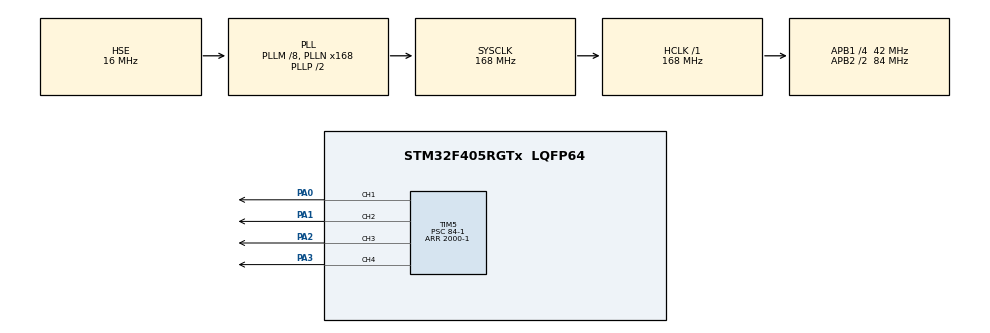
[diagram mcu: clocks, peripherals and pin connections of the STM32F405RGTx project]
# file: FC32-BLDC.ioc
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Mcu.Family=STM32F4
Mcu.Name=STM32F405RGTx
Mcu.Package=LQFP64
NVIC.PriorityGroup=NVIC_PRIORITYGROUP_4
PA0-WKUP.Signal=S_TIM5_CH1
PA1.Signal=S_TIM5_CH2
PA13.Mode=Serial_Wire
PA13.Signal=SYS_JTMS-SWDIO
PA14.Mode=Serial_Wire
PA14.Signal=SYS_JTCK-SWCLK
PA2.Signal=S_TIM5_CH3
PA3.Signal=S_TIM5_CH4
PH0-OSC_IN.Mode=HSE-External-Oscillator
PH0-OSC_IN.Signal=RCC_OSC_IN
PH1-OSC_OUT.Mode=HSE-External-Oscillator
PH1-OSC_OUT.Signal=RCC_OSC_OUT
ProjectManager.HeapSize=0x200
ProjectManager.StackSize=0x400
ProjectManager.TargetToolchain=STM32CubeIDE
RCC.48MHZClocksFreq_Value=84000000
RCC.AHBFreq_Value=168000000
RCC.APB1CLKDivider=RCC_HCLK_DIV4
RCC.APB1Freq_Value=42000000
RCC.APB1TimFreq_Value=84000000
RCC.APB2CLKDivider=RCC_HCLK_DIV2
RCC.APB2Freq_Value=84000000
RCC.APB2TimFreq_Value=168000000
RCC.CortexFreq_Value=168000000
RCC.HCLKFreq_Value=168000000
RCC.HSE_VALUE=16000000
RCC.HSI_VALUE=16000000
RCC.LSE_VALUE=32768
RCC.PLLM=8
RCC.PLLN=168
RCC.PLLSourceVirtual=RCC_PLLSOURCE_HSE
RCC.SYSCLKFreq_VALUE=168000000
RCC.SYSCLKSource=RCC_SYSCLKSOURCE_PLLCLK
RCC.VCOOutputFreq_Value=336000000
SH.S_TIM5_CH1.0=TIM5_CH1,PWM Generation1 CH1
SH.S_TIM5_CH2.0=TIM5_CH2,PWM Generation2 CH2
SH.S_TIM5_CH3.0=TIM5_CH3,PWM Generation3 CH3
SH.S_TIM5_CH4.0=TIM5_CH4,PWM Generation4 CH4
TIM5.Channel-PWM\ Generation1\ CH1=TIM_CHANNEL_1
TIM5.Channel-PWM\ Generation2\ CH2=TIM_CHANNEL_2
TIM5.Channel-PWM\ Generation3\ CH3=TIM_CHANNEL_3
TIM5.Channel-PWM\ Generation4\ CH4=TIM_CHANNEL_4
TIM5.Period=2000-1
TIM5.Prescaler=84-1
VP_TIM5_VS_ClockSourceINT.Mode=Internal
board=custom

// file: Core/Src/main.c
/* USER CODE BEGIN Header */
/**
  ******************************************************************************
  * @file           : main.c
  * @brief          : Main program body
  ******************************************************************************
  * @attention
  *
  * Copyright (c) 2022 STMicroelectronics.
  * All rights reserved.
  *
  * This software is licensed under terms that can be found in the LICENSE file
  * in the root directory of this software component.
  * If no LICENSE file comes with this software, it is provided AS-IS.
  *
  ******************************************************************************
  */
/* USER CODE END Header */
#include "main.h"
#include "tim.h"
#include "gpio.h"

/* USER CODE BEGIN PV */
uint16_t speed = 1100;
/* USER CODE END PV */

void SystemClock_Config(void);

int main(void)
{

  /* MCU Configuration--------------------------------------------------------*/

  /* Reset of all peripherals, Initializes the Flash interface and the Systick. */
  HAL_Init();

  /* Configure the system clock */
  SystemClock_Config();

  /* Initialize all configured peripherals */
  MX_GPIO_Init();
  MX_TIM5_Init();
  /* USER CODE BEGIN 2 */
  HAL_TIM_PWM_Start(&htim5, TIM_CHANNEL_1);
  HAL_TIM_PWM_Start(&htim5, TIM_CHANNEL_2);
  HAL_TIM_PWM_Start(&htim5, TIM_CHANNEL_3);
  HAL_TIM_PWM_Start(&htim5, TIM_CHANNEL_4);

  /* USER CODE END 2 */

  /* Infinite loop */
  while (1)
  {

    /* USER CODE BEGIN 3 */
	  __HAL_TIM_SET_COMPARE(&htim5,TIM_CHANNEL_1,speed);
	  __HAL_TIM_SET_COMPARE(&htim5,TIM_CHANNEL_2,speed);
	  __HAL_TIM_SET_COMPARE(&htim5,TIM_CHANNEL_3,speed);
	  __HAL_TIM_SET_COMPARE(&htim5,TIM_CHANNEL_4,speed);

  }
  /* USER CODE END 3 */
}

void SystemClock_Config(void)
{
  RCC_OscInitTypeDef RCC_OscInitStruct = {0};
  RCC_ClkInitTypeDef RCC_ClkInitStruct = {0};

  /** Configure the main internal regulator output voltage
  */
  __HAL_RCC_PWR_CLK_ENABLE();
  __HAL_PWR_VOLTAGESCALING_CONFIG(PWR_REGULATOR_VOLTAGE_SCALE1);

  /** Initializes the RCC Oscillators according to the specified parameters
  * in the RCC_OscInitTypeDef structure.
  */
  RCC_OscInitStruct.OscillatorType = RCC_OSCILLATORTYPE_HSE;
  RCC_OscInitStruct.HSEState = RCC_HSE_ON;
  RCC_OscInitStruct.PLL.PLLState = RCC_PLL_ON;
  RCC_OscInitStruct.PLL.PLLSource = RCC_PLLSOURCE_HSE;
  RCC_OscInitStruct.PLL.PLLM = 8;
  RCC_OscInitStruct.PLL.PLLN = 168;
  RCC_OscInitStruct.PLL.PLLP = RCC_PLLP_DIV2;
  RCC_OscInitStruct.PLL.PLLQ = 4;
  if (HAL_RCC_OscConfig(&RCC_OscInitStruct) != HAL_OK)
  {
    Error_Handler();
  }

  /** Initializes the CPU, AHB and APB buses clocks
  */
  RCC_ClkInitStruct.ClockType = RCC_CLOCKTYPE_HCLK|RCC_CLOCKTYPE_SYSCLK
                              |RCC_CLOCKTYPE_PCLK1|RCC_CLOCKTYPE_PCLK2;
  RCC_ClkInitStruct.SYSCLKSource = RCC_SYSCLKSOURCE_PLLCLK;
  RCC_ClkInitStruct.AHBCLKDivider = RCC_SYSCLK_DIV1;
  RCC_ClkInitStruct.APB1CLKDivider = RCC_HCLK_DIV4;
  RCC_ClkInitStruct.APB2CLKDivider = RCC_HCLK_DIV2;

  if (HAL_RCC_ClockConfig(&RCC_ClkInitStruct, FLASH_LATENCY_5) != HAL_OK)
  {
    Error_Handler();
  }
}

void Error_Handler(void)
{
  __disable_irq();
  while (1)
  {
  }
}
